# STM32F303 register map
File version: 1.7
Registers are 32-bit, read-write, reset 0x0 unless marked. A register's access mark holds for its fields unless they carry their own. Offsets are from the block's base; [hi:lo] are bit positions; lines under a group give offsets from that group; {n}, {i} and the like mark numbered series.

## USB_FS — Universal serial bus full-speed device interface
Base 0x40005C00
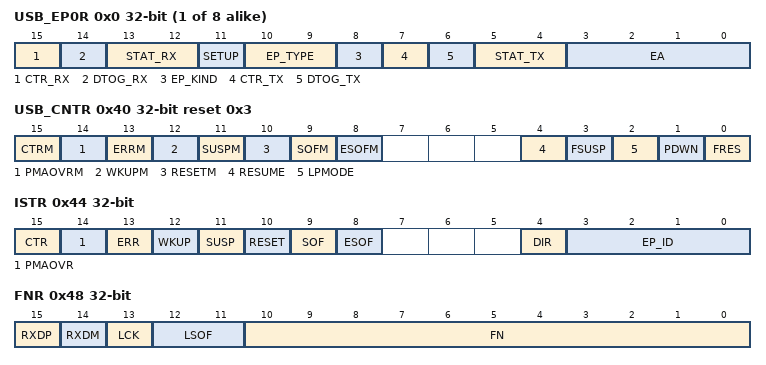
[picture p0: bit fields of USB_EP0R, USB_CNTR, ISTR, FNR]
{0x0+4i} USB_EP{i}R access per field (i=0..7) — endpoint {i} register
  [15] CTR_RX rw — Correct transfer for reception
  [14] DTOG_RX rw — Data Toggle, for reception transfers
  [13:12] STAT_RX rw — Status bits, for reception transfers
  [11] SETUP ro — Setup transaction completed
  [10:9] EP_TYPE rw — Endpoint type
  [8] EP_KIND rw — Endpoint kind
  [7] CTR_TX rw — Correct Transfer for transmission
  [6] DTOG_TX rw — Data Toggle, for transmission transfers
  [5:4] STAT_TX rw — Status bits, for transmission transfers
  [3:0] EA rw — Endpoint address
0x40 USB_CNTR reset 0x3 — control register
  [15] CTRM — Correct transfer interrupt mask
  [14] PMAOVRM — Packet memory area over / underrun interrupt mask
  [13] ERRM — Error interrupt mask
  [12] WKUPM — Wakeup interrupt mask
  [11] SUSPM — Suspend mode interrupt mask
  [10] RESETM — USB reset interrupt mask
  [9] SOFM — Start of frame interrupt mask
  [8] ESOFM — Expected start of frame interrupt mask
  [4] RESUME — Resume request
  [3] FSUSP — Force suspend
  [2] LPMODE — Low-power mode
  [1] PDWN — Power down
  [0] FRES — Force USB Reset
0x44 ISTR access per field — interrupt status register
  [15] CTR ro — Correct transfer
  [14] PMAOVR rw — Packet memory area over / underrun
  [13] ERR rw — Error
  [12] WKUP rw — Wakeup
  [11] SUSP rw — Suspend mode request
  [10] RESET rw — reset request
  [9] SOF rw — start of frame
  [8] ESOF rw — Expected start frame
  [4] DIR ro — Direction of transaction
  [3:0] EP_ID ro — Endpoint Identifier
0x48 FNR ro — frame number register
  [15] RXDP — Receive data + line status
  [14] RXDM — Receive data - line status
  [13] LCK — Locked
  [12:11] LSOF — Lost SOF
  [10:0] FN — Frame number
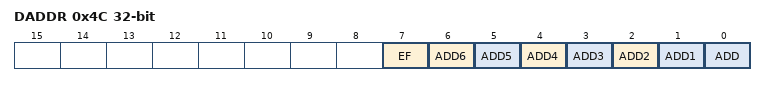
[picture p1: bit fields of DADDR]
0x4C DADDR — device address
  [7] EF — Enable function
  [n] ADD{n} (n=1..6) — Device address
  [0] ADD — Device address
0x50 BTABLE — Buffer table address
  [15:3] BTABLE — Buffer table

## TSC — Touch sensing controller
Base 0x40024000
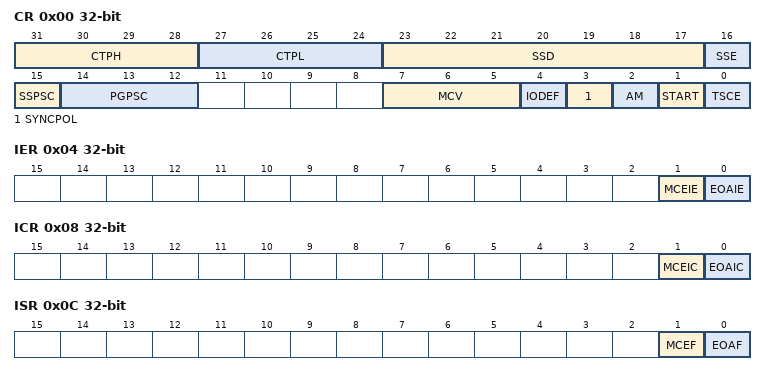
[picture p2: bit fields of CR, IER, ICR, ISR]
0x00 CR — control register
  [31:28] CTPH — Charge transfer pulse high
  [27:24] CTPL — Charge transfer pulse low
  [23:17] SSD — Spread spectrum deviation
  [16] SSE — Spread spectrum enable
  [15] SSPSC — Spread spectrum prescaler
  [14:12] PGPSC — pulse generator prescaler
  [7:5] MCV — Max count value
  [4] IODEF — I/O Default mode
  [3] SYNCPOL — Synchronization pin polarity
  [2] AM — Acquisition mode
  [1] START — Start a new acquisition
  [0] TSCE — Touch sensing controller enable
0x04 IER — interrupt enable register
  [1] MCEIE — Max count error interrupt enable
  [0] EOAIE — End of acquisition interrupt enable
0x08 ICR — interrupt clear register
  [1] MCEIC — Max count error interrupt clear
  [0] EOAIC — End of acquisition interrupt clear
0x0C ISR — interrupt status register
  [1] MCEF — Max count error flag
  [0] EOAF — End of acquisition flag
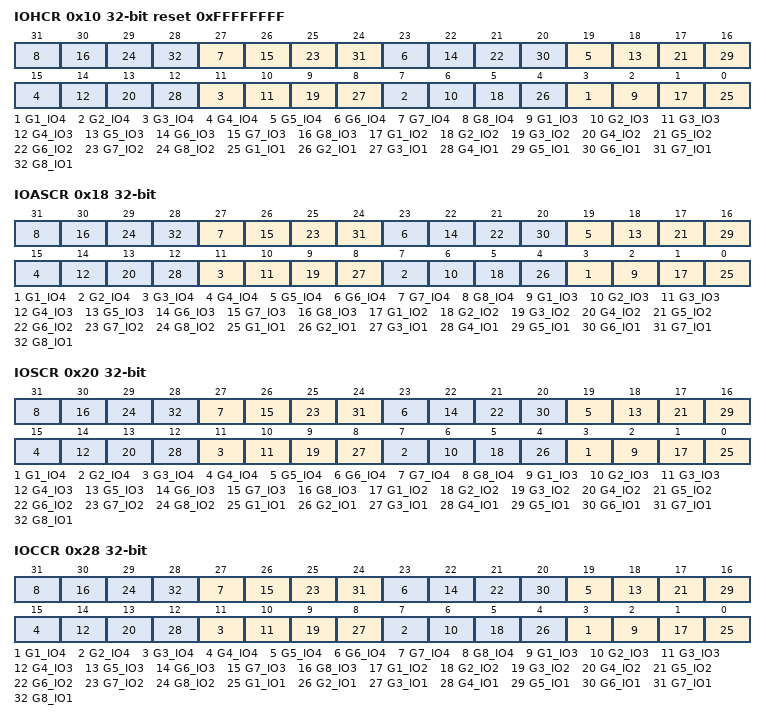
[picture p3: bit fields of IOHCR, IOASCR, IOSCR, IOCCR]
0x10 IOHCR reset 0xFFFFFFFF — I/O hysteresis control register
  [4n-1] G{n}_IO4 (n=1..8) — G{n}_IO4 Schmitt trigger hysteresis mode
  [4n-2] G{n}_IO3 (n=1..8) — G{n}_IO3 Schmitt trigger hysteresis mode
  [4n-3] G{n}_IO2 (n=1..8) — G{n}_IO2 Schmitt trigger hysteresis mode
  [4n-4] G{n}_IO1 (n=1..8) — G{n}_IO1 Schmitt trigger hysteresis mode
0x18 IOASCR — I/O analog switch control register
  [4n-1] G{n}_IO4 (n=1..8) — G{n}_IO4 analog switch enable
  [4n-2] G{n}_IO3 (n=1..8) — G{n}_IO3 analog switch enable
  [4n-3] G{n}_IO2 (n=1..8) — G{n}_IO2 analog switch enable
  [4n-4] G{n}_IO1 (n=1..8) — G{n}_IO1 analog switch enable
0x20 IOSCR — I/O sampling control register
  [4n-1] G{n}_IO4 (n=1..8) — G{n}_IO4 sampling mode
  [4n-2] G{n}_IO3 (n=1..8) — G{n}_IO3 sampling mode
  [4n-3] G{n}_IO2 (n=1..8) — G{n}_IO2 sampling mode
  [4n-4] G{n}_IO1 (n=1..8) — G{n}_IO1 sampling mode
0x28 IOCCR — I/O channel control register
  [4n-1] G{n}_IO4 (n=1..8) — G{n}_IO4 channel mode
  [4n-2] G{n}_IO3 (n=1..8) — G{n}_IO3 channel mode
  [4n-3] G{n}_IO2 (n=1..8) — G{n}_IO2 channel mode
  [4n-4] G{n}_IO1 (n=1..8) — G{n}_IO1 channel mode
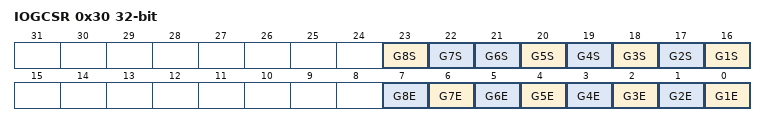
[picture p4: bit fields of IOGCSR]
0x30 IOGCSR access per field — I/O group control status register
  [23] G8S rw — Analog I/O group x status
  [22] G7S rw — Analog I/O group x status
  [n+15] G{n}S ro (n=1..6) — Analog I/O group x status
  [n-1] G{n}E rw (n=1..8) — Analog I/O group x enable
{0x30+4i} IOG{i}CR ro (i=1..8) — I/O group x counter register
  [13:0] CNT — Counter value
